# tviic2d6mddr register map
Vendor: Cypress Semiconductor; Series: tviic2d6mddr; File version: 1.0
CPU: CM7 r0p1, little endian, MPU, FPU, VTOR, 3 interrupt priority bits
Registers are 32-bit, read-write, reset 0x0 unless marked. A register's access mark holds for its fields unless they carry their own. Offsets are from the block's base; [hi:lo] are bit positions; lines under a group give offsets from that group; {n}, {i} and the like mark numbered series.

## HSIOM — High Speed IO Matrix (HSIOM)
Base 0x40300000
{0x0+0x10*i} PRT[{i}] (i=0..19) group — HSIOM port registers
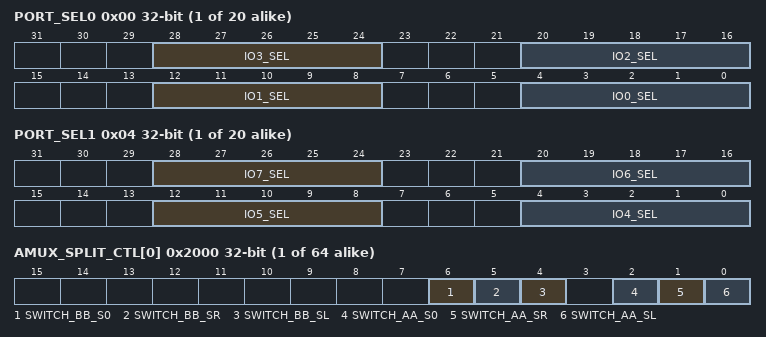
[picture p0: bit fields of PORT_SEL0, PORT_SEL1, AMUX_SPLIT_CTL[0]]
  0x00 PORT_SEL0 — Port selection 0
    [28:24] IO3_SEL — Selects the peripheral connections of Pin 3.
    [20:16] IO2_SEL — Selects the peripheral connections of Pin 2.
    [12:8] IO1_SEL — Selects the peripheral connections of Pin 1.
    [4:0] IO0_SEL — Selects the peripheral connections of Pin 0. Note that available connectivity options vary depending on the device, port and the pin. See the device Datasheet for a list of peripheral connections available at each pin.
      0=GPIO (GPIO controls 'out'); 1=GPIO_DSI (GPIO controls 'out', DSI controls 'output enable'); 2=DSI_DSI (DSI controls 'out' and 'output enable'); 3=DSI_GPIO (DSI controls 'out', GPIO controls 'output enable'); 4=AMUXA (AMUXBUS A); 5=AMUXB (AMUXBUS B); 6=AMUXA_DSI (Analog mux bus A, DSI control); 7=AMUXB_DSI (Analog mux bus B, DSI control); {v}=ACT_{v-8} (Active peripheral {v-8}) (v=8..11); {v}=DS_{v-12} (Deep Sleep peripheral {v-12}) (v=12..15); {v}=ACT_{v-12} (Active peripheral {v-12}) (v=16..27); {v}=DS_{v-24} (Deep Sleep peripheral {v-24}) (v=28..31)
  0x04 PORT_SEL1 — Port selection 1
    [28:24] IO7_SEL — Selects the peripheral connections of Pin 6.
    [20:16] IO6_SEL — Selects the peripheral connections of Pin 5.
    [12:8] IO5_SEL — Selects the peripheral connections of Pin 4.
    [4:0] IO4_SEL — Selects the peripheral connections of Pin 4. See PORT_SEL0 for connection details.
{0x2000+4i} AMUX_SPLIT_CTL[{i}] (i=0..63) — AMUX splitter cell control
  [6] SWITCH_BB_S0 — T-switch control for AMUXBUSB vssa/ground switch.
  [5] SWITCH_BB_SR — T-switch control for Right AMUXBUSB switch.
  [4] SWITCH_BB_SL — T-switch control for Left AMUXBUSB switch.
  [2] SWITCH_AA_S0 — T-switch control for AMUXBUSA vssa/ground switch: '0': switch open. '1': switch closed.
  [1] SWITCH_AA_SR — T-switch control for Right AMUXBUSA switch: '0': switch open. '1': switch closed.
  [0] SWITCH_AA_SL — T-switch control for Left AMUXBUSA switch: '0': switch open. '1': switch closed.
{0x2200+4i} MONITOR_CTL_{i} (i=0..3) — Power/Ground Monitor cell control {i}
  [31:0] MONITOR_EN — control for switch, which connects the power/ground supply to AMUXBUS_A/B respectively when switch is closed: '0': switch open. '1': switch closed.
0x2240 ALT_JTAG_EN — Alternate JTAG IF selection register
  [31] ENABLE — Provides the selection for alternate JTAG IF connectivity. 0: Primary JTAG interface is selected 1: Secondary (alternate) JTAG interface is selected. This connectivity works ONLY in ACTIVE mode.

## SDHC0 (part 3 of 3) — SD/eMMC Host Controller
Base 0x40460000
0x00 WRAP group — MMIO at SDHC wrapper level
  0x00 CTL — Top level wrapper control
    [31] ENABLE — IP Enable: 0: IP disabled, RAM in DeepSleep, SDHC_CORE regs are inaccessible (any attempts to access will result in AHB Error responses), IP is NOT held in reset but the clocks are gated 1: IP enabled, normal operation

## CANFD0 (part 3 of 3) — CAN Controller
Base 0x40520000
Same registers: CANFD1 0x40540000
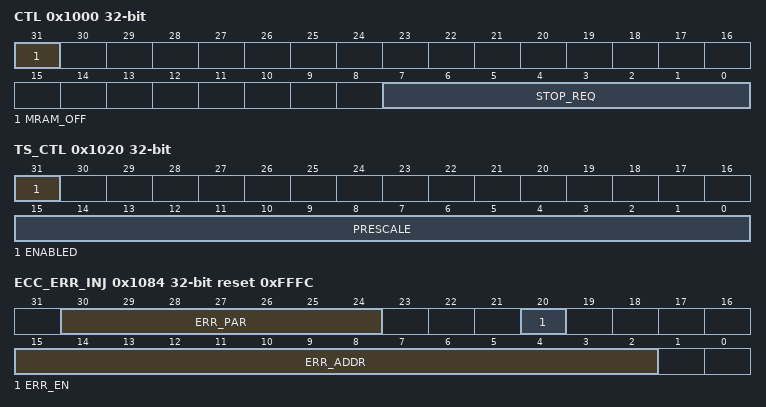
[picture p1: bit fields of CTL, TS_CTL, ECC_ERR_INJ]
0x1000 CTL — Global CAN control register
  [31] MRAM_OFF — MRAM off 0= Default MRAM on (with MRAM retained in DeepSleep). 1= Switch MRAM off (not retained) to save power. Before setting this bit all the CAN channels have to be powered down using the STOP_REQ/ACK bits. When the MRAM is off any access attempt to it is considered an address error (as if MRAM_SIZE=0). After switching the MRAM on again software needs to allow for a certain power up time before MRAM can be used, i.e. before STOP_REQ can be de-asserted. The power up time is equivalent to the system SRAM power up time specified in the CPUSS.RAM_PWR_DELAY_CTL register. MRAM_OFF should be set to 0 prior to transitioning to Hibernate mode.
  [7:0] STOP_REQ — Clock Stop Request for each TTCAN IP . The m_ttcan_clkstop_req of each TTCAN IP is directly driven by these bits.
0x1004 STATUS ro — Global CAN status register
  [7:0] STOP_ACK — Clock Stop Acknowledge for each TTCAN IP. These bits are directly driven by m_ttcan_clkstop_ack of each TTCAN IP. When this bit is set the corresponding TTCAN IP clocks will be gated off, except HCLK will enabled for each AHB write
0x1010 INTR0_CAUSE ro — Consolidated interrupt0 cause register
  [7:0] INT0 — Show pending m_ttcan_int0 of each channel
0x1014 INTR1_CAUSE ro — Consolidated interrupt1 cause register
  [7:0] INT1 — Show pending m_ttcan_int1 of each channel
0x1020 TS_CTL — Time Stamp control register
  [31] ENABLED — Counter enable bit 0 = Count disabled. Stop counting up and keep the counter value 1 = Count enabled. Start counting up from the current value
  [15:0] PRESCALE — Time Stamp counter prescale value. When enabled divide the Host clock (HCLK) by PRESCALE+1 to create Time Stamp clock ticks.
0x1024 TS_CNT — Time Stamp counter value
  [15:0] VALUE — The counter value of the Time Stamp Counter. When enabled this counter will count Time Stamp clock ticks from the pre-scaler. When written this counter and the pre-scaler will reset to 0 (write data is ignored).
0x1080 ECC_CTL — ECC control
  [16] ECC_EN — Enable ECC for CANFD SRAM When disabled also all error injection functionality is disabled.
0x1084 ECC_ERR_INJ reset 0xFFFC — ECC error injection
  [30:24] ERR_PAR — ECC Parity bits to use for ECC error injection at address ERR_ADDR.
  [20] ERR_EN — Enable error injection (ECC_EN must be 1). When this bit is set the error parity (ERR_PAR) will be used when an AHB write is done to the ERR_ADDR address. When the error word is read a single or double error will be reported to the fault structure just like for a real ECC error (even if this bit is no longer set). When this bit is set (and ECC_EN=1) a non-correctable error (ECC or address error) for the ERR_ADDR will not be reported back to the CAN channel or AHB bus.
  [15:2] ERR_ADDR — Specifies the address of the word where an error will be injected on write or an non-correctable error will be suppressed. When the ERR_EN bit is set an error parity (ERR_PAR) is injected when any write, from bus or a CAN channel, is done to this address. When the ERR_EN bit is set and the access address matches ERR_ADDR then a non-correctable ECC error or an Address error will NOT result in a bus error or CAN channel shutdown. Note that error reporting to the fault structure cannot be suppressed.
